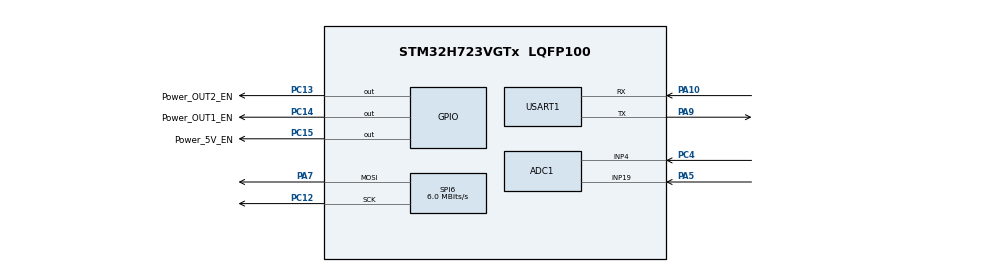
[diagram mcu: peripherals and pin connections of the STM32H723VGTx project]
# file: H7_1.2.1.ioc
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ADC1.Channel-0\#ChannelRegularConversion=ADC_CHANNEL_4
ADC1.Channel-1\#ChannelRegularConversion=ADC_CHANNEL_19
ADC1.ClockPrescaler=ADC_CLOCK_ASYNC_DIV64
ADC1.ContinuousConvMode=ENABLE
ADC1.ConversionDataManagement=ADC_CONVERSIONDATA_DMA_CIRCULAR
ADC1.NbrOfConversion=2
ADC1.NbrOfConversionFlag=1
ADC1.OffsetNumber-0\#ChannelRegularConversion=ADC_OFFSET_NONE
ADC1.OffsetNumber-1\#ChannelRegularConversion=ADC_OFFSET_NONE
ADC1.OffsetSignedSaturation-0\#ChannelRegularConversion=DISABLE
ADC1.OffsetSignedSaturation-1\#ChannelRegularConversion=DISABLE
ADC1.Rank-0\#ChannelRegularConversion=1
ADC1.Rank-1\#ChannelRegularConversion=2
ADC1.SamplingTime-0\#ChannelRegularConversion=ADC_SAMPLETIME_32CYCLES_5
ADC1.SamplingTime-1\#ChannelRegularConversion=ADC_SAMPLETIME_32CYCLES_5
ADC1.master=1
Bdma.Request0=SPI6_TX
Bdma.RequestsNb=1
Bdma.SPI6_TX.0.Direction=DMA_MEMORY_TO_PERIPH
Bdma.SPI6_TX.0.EventEnable=DISABLE
Bdma.SPI6_TX.0.Instance=BDMA_Channel0
Bdma.SPI6_TX.0.MemDataAlignment=DMA_MDATAALIGN_BYTE
Bdma.SPI6_TX.0.MemInc=DMA_MINC_ENABLE
Bdma.SPI6_TX.0.Mode=DMA_NORMAL
Bdma.SPI6_TX.0.PeriphDataAlignment=DMA_PDATAALIGN_BYTE
Bdma.SPI6_TX.0.PeriphInc=DMA_PINC_DISABLE
Bdma.SPI6_TX.0.Polarity=HAL_DMAMUX_REQ_GEN_RISING
Bdma.SPI6_TX.0.Priority=DMA_PRIORITY_LOW
Bdma.SPI6_TX.0.RequestNumber=1
Bdma.SPI6_TX.0.SignalID=NONE
Bdma.SPI6_TX.0.SyncEnable=DISABLE
Bdma.SPI6_TX.0.SyncPolarity=HAL_DMAMUX_SYNC_NO_EVENT
Bdma.SPI6_TX.0.SyncRequestNumber=1
Bdma.SPI6_TX.0.SyncSignalID=NONE
CORTEX_M7.CPU_ICache=Enabled
CORTEX_M7.MPU_Control=__NULL
CORTEX_M7.default_mode_Activation=1
Dma.ADC1.0.Direction=DMA_PERIPH_TO_MEMORY
Dma.ADC1.0.EventEnable=DISABLE
Dma.ADC1.0.FIFOMode=DMA_FIFOMODE_DISABLE
Dma.ADC1.0.Instance=DMA1_Stream0
Dma.ADC1.0.MemDataAlignment=DMA_MDATAALIGN_HALFWORD
Dma.ADC1.0.MemInc=DMA_MINC_ENABLE
Dma.ADC1.0.Mode=DMA_CIRCULAR
Dma.ADC1.0.PeriphDataAlignment=DMA_PDATAALIGN_HALFWORD
Dma.ADC1.0.PeriphInc=DMA_PINC_DISABLE
Dma.ADC1.0.Polarity=HAL_DMAMUX_REQ_GEN_RISING
Dma.ADC1.0.Priority=DMA_PRIORITY_LOW
Dma.ADC1.0.RequestNumber=1
Dma.ADC1.0.SignalID=NONE
Dma.ADC1.0.SyncEnable=DISABLE
Dma.ADC1.0.SyncPolarity=HAL_DMAMUX_SYNC_NO_EVENT
Dma.ADC1.0.SyncRequestNumber=1
Dma.ADC1.0.SyncSignalID=NONE
Dma.Request0=ADC1
Mcu.Family=STM32H7
Mcu.Name=STM32H723VGTx
Mcu.Package=LQFP100
NVIC.BDMA_Channel0_IRQn=true\:0\:0\:false\:false\:true\:false\:true\:true
NVIC.DMA1_Stream0_IRQn=true\:0\:0\:false\:false\:true\:false\:true\:true
NVIC.PriorityGroup=NVIC_PRIORITYGROUP_4
NVIC.SPI6_IRQn=true\:0\:0\:false\:false\:true\:false\:true\:true
PA10.Mode=Asynchronous
PA10.Signal=USART1_RX
PA13(JTMS/SWDIO).Mode=Serial_Wire
PA13(JTMS/SWDIO).Signal=DEBUG_JTMS-SWDIO
PA14(JTCK/SWCLK).Mode=Serial_Wire
PA14(JTCK/SWCLK).Signal=DEBUG_JTCK-SWCLK
PA5.Signal=ADCx_INP19
PA7.Mode=TX_Only_Simplex_Unidirect_Master
PA7.Signal=SPI6_MOSI
PA9.Mode=Asynchronous
PA9.Signal=USART1_TX
PC12.Mode=TX_Only_Simplex_Unidirect_Master
PC12.Signal=SPI6_SCK
PC13.GPIO_Label=Power_OUT2_EN
PC13.Signal=GPIO_Output
PC14-OSC32_IN.GPIO_Label=Power_OUT1_EN
PC14-OSC32_IN.Signal=GPIO_Output
PC15-OSC32_OUT.GPIO_Label=Power_5V_EN
PC15-OSC32_OUT.Signal=GPIO_Output
PC4.Signal=ADCx_INP4
PH0-OSC_IN.Mode=HSE-External-Oscillator
PH0-OSC_IN.Signal=RCC_OSC_IN
PH1-OSC_OUT.Mode=HSE-External-Oscillator
PH1-OSC_OUT.Signal=RCC_OSC_OUT
ProjectManager.HeapSize=0x200
ProjectManager.StackSize=0x400
ProjectManager.TargetToolchain=STM32CubeIDE
RCC.ADCCLockSelection=RCC_ADCCLKSOURCE_CLKP
RCC.ADCFreq_Value=64000000
RCC.APB1Freq_Value=137500000
RCC.APB2Freq_Value=137500000
RCC.APB3Freq_Value=137500000
RCC.APB4Freq_Value=137500000
RCC.CortexFreq_Value=550000000
RCC.D1PPRE=RCC_APB3_DIV2
RCC.D2PPRE1=RCC_APB1_DIV2
RCC.D2PPRE2=RCC_APB2_DIV2
RCC.D3PPRE=RCC_APB4_DIV2
RCC.DIVM1=3
RCC.DIVM2=2
RCC.DIVN1=68
RCC.DIVN2=16
RCC.DIVP1=1
RCC.HCLKFreq_Value=275000000
RCC.HPRE=RCC_HCLK_DIV2
RCC.HSE_VALUE=24000000
RCC.PLL2FRACN=0
RCC.PLL3FRACN=0
RCC.PLLFRACN=6144
RCC.PLLSourceVirtual=RCC_PLLSOURCE_HSE
RCC.SPI6CLockSelection=RCC_SPI6CLKSOURCE_HSE
RCC.SYSCLKFreq_VALUE=550000000
RCC.SYSCLKSource=RCC_SYSCLKSOURCE_PLLCLK
RCC.USBFreq_Value=275000000
SH.ADCx_INP19.0=ADC1_INP19,IN19-Single-Ended
SH.ADCx_INP4.0=ADC1_INP4,IN4-Single-Ended
SPI6.BaudRatePrescaler=SPI_BAUDRATEPRESCALER_4
SPI6.CLKPhase=SPI_PHASE_2EDGE
SPI6.CalculateBaudRate=6.0 MBits/s
SPI6.DataSize=SPI_DATASIZE_8BIT
SPI6.Direction=SPI_DIRECTION_2LINES_TXONLY
SPI6.Mode=SPI_MODE_MASTER
SPI6.VirtualType=VM_MASTER
USART1.VirtualMode-Asynchronous=VM_ASYNC
VP_MEMORYMAP_VS_MEMORYMAP.Mode=CurAppReg
board=custom

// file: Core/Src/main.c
/* USER CODE BEGIN Header */
/**
  ******************************************************************************
  * @file           : main.c
  * @brief          : Main program body
  ******************************************************************************
  * @attention
  *
  * Copyright (c) 2026 STMicroelectronics.
  * All rights reserved.
  *
  * This software is licensed under terms that can be found in the LICENSE file
  * in the root directory of this software component.
  * If no LICENSE file comes with this software, it is provided AS-IS.
  *
  ******************************************************************************
  */
/* USER CODE END Header */
#include "main.h"
#include "adc.h"
#include "bdma.h"
#include "dma.h"
#include "spi.h"
#include "usart.h"
#include "gpio.h"

/* USER CODE BEGIN Includes */
#include <stdio.h>
#include <string.h>
/* USER CODE END Includes */

void SystemClock_Config(void);
void PeriphCommonClock_Config(void);

/* USER CODE BEGIN 0 */
uint16_t adc_val[2];
float vbus;

uint8_t uart_tx_buf[64];
volatile uint8_t uart1_tx_busy = 0;
/* USER CODE END 0 */

int main(void)
{

  /* Enable the CPU Cache */

  /* Enable I-Cache---------------------------------------------------------*/
  SCB_EnableICache();

  /* MCU Configuration--------------------------------------------------------*/

  /* Reset of all peripherals, Initializes the Flash interface and the Systick. */
  HAL_Init();

  /* Configure the system clock */
  SystemClock_Config();

  /* Configure the peripherals common clocks */
  PeriphCommonClock_Config();

  /* Initialize all configured peripherals */
  MX_GPIO_Init();
  MX_BDMA_Init();
  MX_DMA_Init();
  MX_SPI6_Init();
  MX_USART1_UART_Init();
  MX_ADC1_Init();
  /* USER CODE BEGIN 2 */
  HAL_ADCEx_Calibration_Start(&hadc1, ADC_CALIB_OFFSET, ADC_SINGLE_ENDED);
  HAL_ADC_Start_DMA(&hadc1, (uint32_t *)adc_val,2);
  /* USER CODE END 2 */

  /* Infinite loop */
  /* USER CODE BEGIN WHILE */
  while (1)
  {
    char txbuf[64];
    float vbus = (adc_val[0] * 3.3f / 65535.0f) * 11.0f;

    int len = snprintf(txbuf, sizeof(txbuf), "vbus=%.3f V\r\n", vbus);
    HAL_UART_Transmit(&huart1, (uint8_t*)txbuf, len, 0xFFFF);
    HAL_Delay(100);
    /* USER CODE END WHILE */

  }
}

void SystemClock_Config(void)
{
  RCC_OscInitTypeDef RCC_OscInitStruct = {0};
  RCC_ClkInitTypeDef RCC_ClkInitStruct = {0};

  /** Supply configuration update enable
  */
  HAL_PWREx_ConfigSupply(PWR_LDO_SUPPLY);

  /** Configure the main internal regulator output voltage
  */
  __HAL_PWR_VOLTAGESCALING_CONFIG(PWR_REGULATOR_VOLTAGE_SCALE0);

  while(!__HAL_PWR_GET_FLAG(PWR_FLAG_VOSRDY)) {}

  /** Initializes the RCC Oscillators according to the specified parameters
  * in the RCC_OscInitTypeDef structure.
  */
  RCC_OscInitStruct.OscillatorType = RCC_OSCILLATORTYPE_HSI|RCC_OSCILLATORTYPE_HSE;
  RCC_OscInitStruct.HSEState = RCC_HSE_ON;
  RCC_OscInitStruct.HSIState = RCC_HSI_DIV1;
  RCC_OscInitStruct.HSICalibrationValue = 64;
  RCC_OscInitStruct.PLL.PLLState = RCC_PLL_ON;
  RCC_OscInitStruct.PLL.PLLSource = RCC_PLLSOURCE_HSE;
  RCC_OscInitStruct.PLL.PLLM = 3;
  RCC_OscInitStruct.PLL.PLLN = 68;
  RCC_OscInitStruct.PLL.PLLP = 1;
  RCC_OscInitStruct.PLL.PLLQ = 2;
  RCC_OscInitStruct.PLL.PLLR = 2;
  RCC_OscInitStruct.PLL.PLLRGE = RCC_PLL1VCIRANGE_3;
  RCC_OscInitStruct.PLL.PLLVCOSEL = RCC_PLL1VCOWIDE;
  RCC_OscInitStruct.PLL.PLLFRACN = 6144;
  if (HAL_RCC_OscConfig(&RCC_OscInitStruct) != HAL_OK)
  {
    Error_Handler();
  }

  /** Initializes the CPU, AHB and APB buses clocks
  */
  RCC_ClkInitStruct.ClockType = RCC_CLOCKTYPE_HCLK|RCC_CLOCKTYPE_SYSCLK
                              |RCC_CLOCKTYPE_PCLK1|RCC_CLOCKTYPE_PCLK2
                              |RCC_CLOCKTYPE_D3PCLK1|RCC_CLOCKTYPE_D1PCLK1;
  RCC_ClkInitStruct.SYSCLKSource = RCC_SYSCLKSOURCE_PLLCLK;
  RCC_ClkInitStruct.SYSCLKDivider = RCC_SYSCLK_DIV1;
  RCC_ClkInitStruct.AHBCLKDivider = RCC_HCLK_DIV2;
  RCC_ClkInitStruct.APB3CLKDivider = RCC_APB3_DIV2;
  RCC_ClkInitStruct.APB1CLKDivider = RCC_APB1_DIV2;
  RCC_ClkInitStruct.APB2CLKDivider = RCC_APB2_DIV2;
  RCC_ClkInitStruct.APB4CLKDivider = RCC_APB4_DIV2;

  if (HAL_RCC_ClockConfig(&RCC_ClkInitStruct, FLASH_LATENCY_3) != HAL_OK)
  {
    Error_Handler();
  }
}

void PeriphCommonClock_Config(void)
{
  RCC_PeriphCLKInitTypeDef PeriphClkInitStruct = {0};

  /** Initializes the peripherals clock
  */
  PeriphClkInitStruct.PeriphClockSelection = RCC_PERIPHCLK_CKPER;
  PeriphClkInitStruct.CkperClockSelection = RCC_CLKPSOURCE_HSI;
  if (HAL_RCCEx_PeriphCLKConfig(&PeriphClkInitStruct) != HAL_OK)
  {
    Error_Handler();
  }
}

void Error_Handler(void)
{
  __disable_irq();
  while (1)
  {
  }
}
